AUTOSAR XML (schema 00051)
package /Components
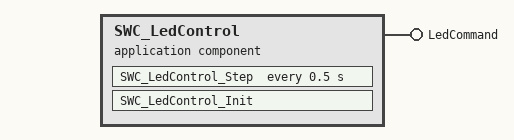
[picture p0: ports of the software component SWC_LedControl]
  application sw component type SWC_LedControl
    provide port LedCommand: nonqueued-sender-com-spec{data-element=LedCommand, init-value=0}, provided-interface=LedCommand
    behavior SWC_LedControl_IB: handle-termination-and-restart=NO-SUPPORT
      timing event Event_SWC_LedControl_Step: start-on-event=SWC_LedControl_Step, period=0.5
      runnable SWC_LedControl_Init
      runnable SWC_LedControl_Step
        data-write-access:
          access OUT_LedCommand_LedCommand: accessed-variable=LedCommand.LedCommand
